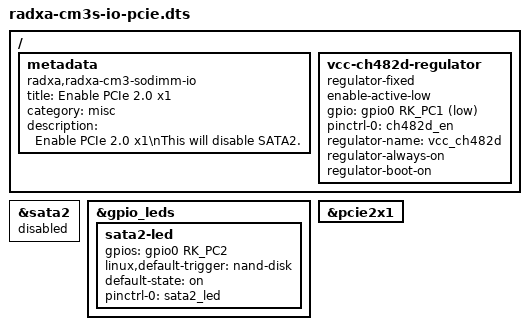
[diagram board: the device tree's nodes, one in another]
/dts-v1/;
/plugin/;

#include <dt-bindings/gpio/gpio.h>
#include <dt-bindings/pinctrl/rockchip.h>

/ {
	metadata {
		title = "Enable PCIe 2.0 x1";
		compatible = "radxa,radxa-cm3-sodimm-io";
		category = "misc";
		description = "Enable PCIe 2.0 x1\nThis will disable SATA2.";
	};

	fragment@0 {
		target-path = "/";

		__overlay__ {
			vcc-ch482d-regulator {
				compatible = "regulator-fixed";
				enable-active-low;
				gpio = <&gpio0 RK_PC1 GPIO_ACTIVE_LOW>;
				pinctrl-names = "default";
				pinctrl-0 = <&ch482d_en>;
				regulator-name = "vcc_ch482d";
				regulator-always-on;
				regulator-boot-on;
			};
		};
	};

	fragment@1 {
		target = <&sata2>;

		__overlay__ {
			status = "disabled";
		};
	};

	fragment@2 {
		target = <&gpio_leds>;

		__overlay__ {
			sata2-led {
				gpios = <&gpio0 RK_PC2 GPIO_ACTIVE_HIGH>;
				linux,default-trigger = "nand-disk";
				default-state = "on";
				pinctrl-0 = <&sata2_led>;
			};
		};
	};

	fragment@3 {
		target = <&pcie2x1>;

		__overlay__ {
			status = "okay";
		};
	};
};
